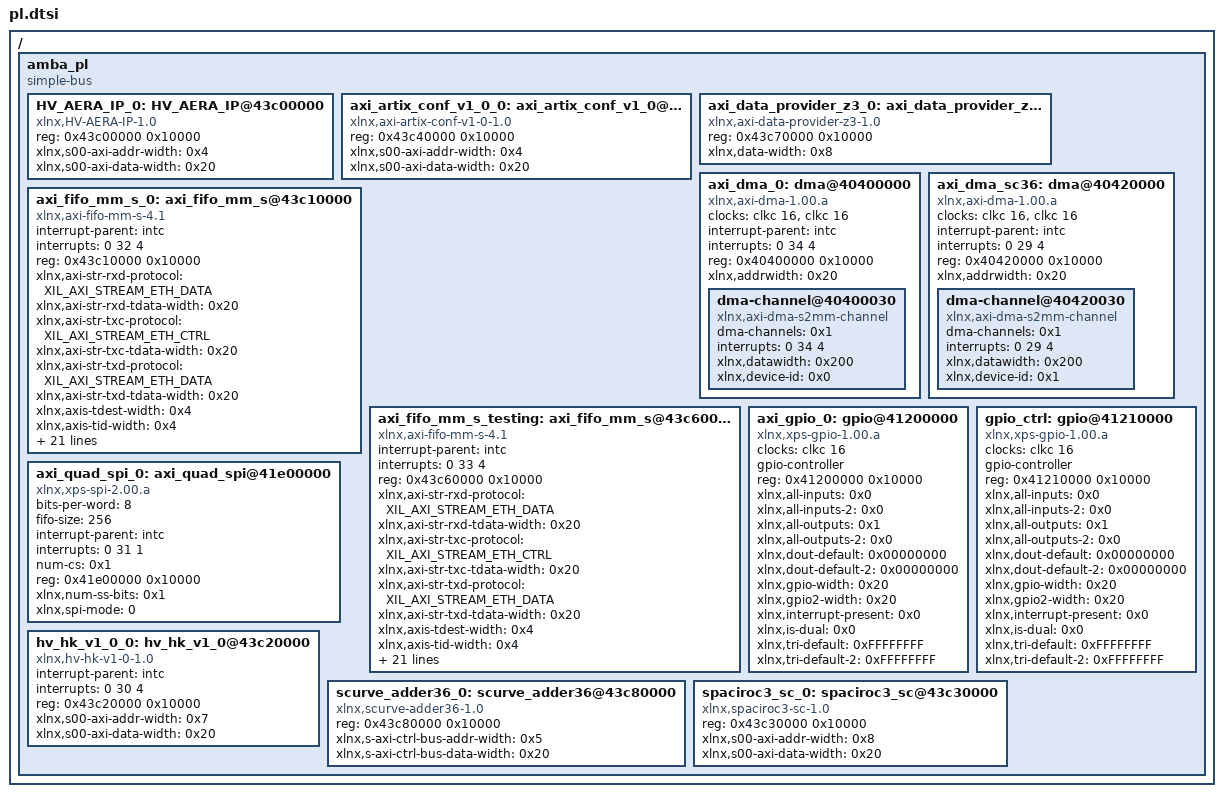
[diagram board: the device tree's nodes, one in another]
/*
 * CAUTION: This file is automatically generated by Xilinx.
 * Version:  
 * Today is: Tue Jan 21 17:48:53 2020
 */


/ {
	amba_pl: amba_pl {
		#address-cells = <1>;
		#size-cells = <1>;
		compatible = "simple-bus";
		ranges ;
		HV_AERA_IP_0: HV_AERA_IP@43c00000 {
			compatible = "xlnx,HV-AERA-IP-1.0";
			reg = <0x43c00000 0x10000>;
			xlnx,s00-axi-addr-width = <0x4>;
			xlnx,s00-axi-data-width = <0x20>;
		};
		axi_artix_conf_v1_0_0: axi_artix_conf_v1_0@43c40000 {
			compatible = "xlnx,axi-artix-conf-v1-0-1.0";
			reg = <0x43c40000 0x10000>;
			xlnx,s00-axi-addr-width = <0x4>;
			xlnx,s00-axi-data-width = <0x20>;
		};
		axi_data_provider_z3_0: axi_data_provider_z3@43c70000 {
			compatible = "xlnx,axi-data-provider-z3-1.0";
			reg = <0x43c70000 0x10000>;
			xlnx,data-width = <0x8>;
		};
		axi_dma_0: dma@40400000 {
			#dma-cells = <1>;
			clock-names = "s_axi_lite_aclk", "m_axi_sg_aclk", "m_axi_s2mm_aclk";
			clocks = <&clkc 16>, <&clkc 16>;
			compatible = "xlnx,axi-dma-1.00.a";
			interrupt-names = "s2mm_introut";
			interrupt-parent = <&intc>;
			interrupts = <0 34 4>;
			reg = <0x40400000 0x10000>;
			xlnx,addrwidth = <0x20>;
			dma-channel@40400030 {
				compatible = "xlnx,axi-dma-s2mm-channel";
				dma-channels = <0x1>;
				interrupts = <0 34 4>;
				xlnx,datawidth = <0x200>;
				xlnx,device-id = <0x0>;
			};
		};
		axi_dma_sc36: dma@40420000 {
			#dma-cells = <1>;
			clock-names = "s_axi_lite_aclk", "m_axi_sg_aclk", "m_axi_s2mm_aclk";
			clocks = <&clkc 16>, <&clkc 16>;
			compatible = "xlnx,axi-dma-1.00.a";
			interrupt-names = "s2mm_introut";
			interrupt-parent = <&intc>;
			interrupts = <0 29 4>;
			reg = <0x40420000 0x10000>;
			xlnx,addrwidth = <0x20>;
			dma-channel@40420030 {
				compatible = "xlnx,axi-dma-s2mm-channel";
				dma-channels = <0x1>;
				interrupts = <0 29 4>;
				xlnx,datawidth = <0x200>;
				xlnx,device-id = <0x1>;
			};
		};
		axi_fifo_mm_s_0: axi_fifo_mm_s@43c10000 {
			compatible = "xlnx,axi-fifo-mm-s-4.1";
			interrupt-names = "interrupt";
			interrupt-parent = <&intc>;
			interrupts = <0 32 4>;
			reg = <0x43c10000 0x10000>;
			xlnx,axi-str-rxd-protocol = "XIL_AXI_STREAM_ETH_DATA";
			xlnx,axi-str-rxd-tdata-width = <0x20>;
			xlnx,axi-str-txc-protocol = "XIL_AXI_STREAM_ETH_CTRL";
			xlnx,axi-str-txc-tdata-width = <0x20>;
			xlnx,axi-str-txd-protocol = "XIL_AXI_STREAM_ETH_DATA";
			xlnx,axi-str-txd-tdata-width = <0x20>;
			xlnx,axis-tdest-width = <0x4>;
			xlnx,axis-tid-width = <0x4>;
			xlnx,axis-tuser-width = <0x4>;
			xlnx,data-interface-type = <0x0>;
			xlnx,has-axis-tdest = <0x0>;
			xlnx,has-axis-tid = <0x0>;
			xlnx,has-axis-tkeep = <0x0>;
			xlnx,has-axis-tstrb = <0x0>;
			xlnx,has-axis-tuser = <0x0>;
			xlnx,rx-fifo-depth = <0x200>;
			xlnx,rx-fifo-pe-threshold = <0x2>;
			xlnx,rx-fifo-pf-threshold = <0x1fb>;
			xlnx,s-axi-id-width = <0x4>;
			xlnx,s-axi4-data-width = <0x20>;
			xlnx,select-xpm = <0x0>;
			xlnx,tx-fifo-depth = <0x1000>;
			xlnx,tx-fifo-pe-threshold = <0x2>;
			xlnx,tx-fifo-pf-threshold = <0xffb>;
			xlnx,use-rx-cut-through = <0x0>;
			xlnx,use-rx-data = <0x0>;
			xlnx,use-tx-ctrl = <0x0>;
			xlnx,use-tx-cut-through = <0x0>;
			xlnx,use-tx-data = <0x1>;
		};
		axi_fifo_mm_s_testing: axi_fifo_mm_s@43c60000 {
			compatible = "xlnx,axi-fifo-mm-s-4.1";
			interrupt-names = "interrupt";
			interrupt-parent = <&intc>;
			interrupts = <0 33 4>;
			reg = <0x43c60000 0x10000>;
			xlnx,axi-str-rxd-protocol = "XIL_AXI_STREAM_ETH_DATA";
			xlnx,axi-str-rxd-tdata-width = <0x20>;
			xlnx,axi-str-txc-protocol = "XIL_AXI_STREAM_ETH_CTRL";
			xlnx,axi-str-txc-tdata-width = <0x20>;
			xlnx,axi-str-txd-protocol = "XIL_AXI_STREAM_ETH_DATA";
			xlnx,axi-str-txd-tdata-width = <0x20>;
			xlnx,axis-tdest-width = <0x4>;
			xlnx,axis-tid-width = <0x4>;
			xlnx,axis-tuser-width = <0x4>;
			xlnx,data-interface-type = <0x0>;
			xlnx,has-axis-tdest = <0x0>;
			xlnx,has-axis-tid = <0x0>;
			xlnx,has-axis-tkeep = <0x0>;
			xlnx,has-axis-tstrb = <0x0>;
			xlnx,has-axis-tuser = <0x0>;
			xlnx,rx-fifo-depth = <0x200>;
			xlnx,rx-fifo-pe-threshold = <0x2>;
			xlnx,rx-fifo-pf-threshold = <0x1fb>;
			xlnx,s-axi-id-width = <0x4>;
			xlnx,s-axi4-data-width = <0x20>;
			xlnx,select-xpm = <0x0>;
			xlnx,tx-fifo-depth = <0x200>;
			xlnx,tx-fifo-pe-threshold = <0x2>;
			xlnx,tx-fifo-pf-threshold = <0x1fb>;
			xlnx,use-rx-cut-through = <0x0>;
			xlnx,use-rx-data = <0x1>;
			xlnx,use-tx-ctrl = <0x0>;
			xlnx,use-tx-cut-through = <0x0>;
			xlnx,use-tx-data = <0x1>;
		};
		axi_gpio_0: gpio@41200000 {
			#gpio-cells = <3>;
			clock-names = "s_axi_aclk";
			clocks = <&clkc 16>;
			compatible = "xlnx,xps-gpio-1.00.a";
			gpio-controller ;
			reg = <0x41200000 0x10000>;
			xlnx,all-inputs = <0x0>;
			xlnx,all-inputs-2 = <0x0>;
			xlnx,all-outputs = <0x1>;
			xlnx,all-outputs-2 = <0x0>;
			xlnx,dout-default = <0x00000000>;
			xlnx,dout-default-2 = <0x00000000>;
			xlnx,gpio-width = <0x20>;
			xlnx,gpio2-width = <0x20>;
			xlnx,interrupt-present = <0x0>;
			xlnx,is-dual = <0x0>;
			xlnx,tri-default = <0xFFFFFFFF>;
			xlnx,tri-default-2 = <0xFFFFFFFF>;
		};
		axi_quad_spi_0: axi_quad_spi@41e00000 {
			bits-per-word = <8>;
			compatible = "xlnx,xps-spi-2.00.a";
			fifo-size = <256>;
			interrupt-names = "ip2intc_irpt";
			interrupt-parent = <&intc>;
			interrupts = <0 31 1>;
			num-cs = <0x1>;
			reg = <0x41e00000 0x10000>;
			xlnx,num-ss-bits = <0x1>;
			xlnx,spi-mode = <0>;
		};
		gpio_ctrl: gpio@41210000 {
			#gpio-cells = <3>;
			clock-names = "s_axi_aclk";
			clocks = <&clkc 16>;
			compatible = "xlnx,xps-gpio-1.00.a";
			gpio-controller ;
			reg = <0x41210000 0x10000>;
			xlnx,all-inputs = <0x0>;
			xlnx,all-inputs-2 = <0x0>;
			xlnx,all-outputs = <0x1>;
			xlnx,all-outputs-2 = <0x0>;
			xlnx,dout-default = <0x00000000>;
			xlnx,dout-default-2 = <0x00000000>;
			xlnx,gpio-width = <0x20>;
			xlnx,gpio2-width = <0x20>;
			xlnx,interrupt-present = <0x0>;
			xlnx,is-dual = <0x0>;
			xlnx,tri-default = <0xFFFFFFFF>;
			xlnx,tri-default-2 = <0xFFFFFFFF>;
		};
		hv_hk_v1_0_0: hv_hk_v1_0@43c20000 {
			compatible = "xlnx,hv-hk-v1-0-1.0";
			interrupt-names = "intr_out";
			interrupt-parent = <&intc>;
			interrupts = <0 30 4>;
			reg = <0x43c20000 0x10000>;
			xlnx,s00-axi-addr-width = <0x7>;
			xlnx,s00-axi-data-width = <0x20>;
		};
		scurve_adder36_0: scurve_adder36@43c80000 {
			compatible = "xlnx,scurve-adder36-1.0";
			reg = <0x43c80000 0x10000>;
			xlnx,s-axi-ctrl-bus-addr-width = <0x5>;
			xlnx,s-axi-ctrl-bus-data-width = <0x20>;
		};
		spaciroc3_sc_0: spaciroc3_sc@43c30000 {
			compatible = "xlnx,spaciroc3-sc-1.0";
			reg = <0x43c30000 0x10000>;
			xlnx,s00-axi-addr-width = <0x8>;
			xlnx,s00-axi-data-width = <0x20>;
		};
	};
};
